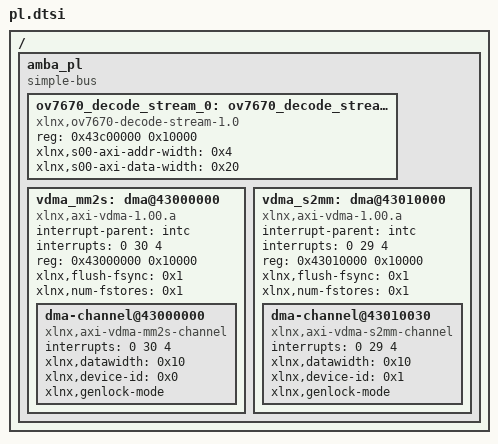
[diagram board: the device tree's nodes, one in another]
/*
 * CAUTION: This file is automatically generated by Xilinx.
 * Version:  
 * Today is: Thu Apr 25 19:15:05 2019
*/


/ {
	amba_pl: amba_pl {
		#address-cells = <1>;
		#size-cells = <1>;
		compatible = "simple-bus";
		ranges ;
		ov7670_decode_stream_0: ov7670_decode_stream@43c00000 {
			compatible = "xlnx,ov7670-decode-stream-1.0";
			reg = <0x43c00000 0x10000>;
			xlnx,s00-axi-addr-width = <0x4>;
			xlnx,s00-axi-data-width = <0x20>;
		};
		vdma_mm2s: dma@43000000 {
			#dma-cells = <1>;
			compatible = "xlnx,axi-vdma-1.00.a";
			interrupt-parent = <&intc>;
			interrupts = <0 30 4>;
			reg = <0x43000000 0x10000>;
			xlnx,flush-fsync = <0x1>;
			xlnx,num-fstores = <0x1>;
			dma-channel@43000000 {
				compatible = "xlnx,axi-vdma-mm2s-channel";
				interrupts = <0 30 4>;
				xlnx,datawidth = <0x10>;
				xlnx,device-id = <0x0>;
				xlnx,genlock-mode ;
			};
		};
		vdma_s2mm: dma@43010000 {
			#dma-cells = <1>;
			compatible = "xlnx,axi-vdma-1.00.a";
			interrupt-parent = <&intc>;
			interrupts = <0 29 4>;
			reg = <0x43010000 0x10000>;
			xlnx,flush-fsync = <0x1>;
			xlnx,num-fstores = <0x1>;
			dma-channel@43010030 {
				compatible = "xlnx,axi-vdma-s2mm-channel";
				interrupts = <0 29 4>;
				xlnx,datawidth = <0x10>;
				xlnx,device-id = <0x1>;
				xlnx,genlock-mode ;
			};
		};
	};
};
